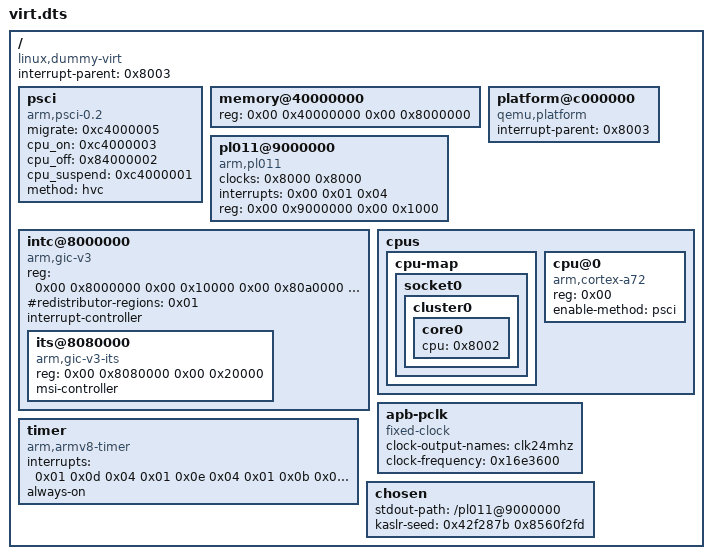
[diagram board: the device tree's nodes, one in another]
/dts-v1/;

/ {
	interrupt-parent = <0x8003>;
	#size-cells = <0x02>;
	#address-cells = <0x02>;
	compatible = "linux,dummy-virt";

	psci {
		migrate = <0xc4000005>;
		cpu_on = <0xc4000003>;
		cpu_off = <0x84000002>;
		cpu_suspend = <0xc4000001>;
		method = "hvc";
		compatible = "arm,psci-0.2\0arm,psci";
	};
	
	memory@40000000 {
		reg = <0x00 0x40000000 0x00 0x8000000>;
		device_type = "memory";
	};

	platform@c000000 {
		interrupt-parent = <0x8003>;
		ranges = <0x00 0x00 0xc000000 0x2000000>;
		#address-cells = <0x01>;
		#size-cells = <0x01>;
		compatible = "qemu,platform\0simple-bus";
	};

	pl011@9000000 {
		clock-names = "uartclk\0apb_pclk";
		clocks = <0x8000 0x8000>;
		interrupts = <0x00 0x01 0x04>;
		reg = <0x00 0x9000000 0x00 0x1000>;
		compatible = "arm,pl011\0arm,primecell";
	};

	intc@8000000 {
		phandle = <0x8003>;
		reg = <0x00 0x8000000 0x00 0x10000 0x00 0x80a0000 0x00 0xf60000>;
		#redistributor-regions = <0x01>;
		compatible = "arm,gic-v3";
		ranges;
		#size-cells = <0x02>;
		#address-cells = <0x02>;
		interrupt-controller;
		#interrupt-cells = <0x03>;

		its@8080000 {
			phandle = <0x8004>;
			reg = <0x00 0x8080000 0x00 0x20000>;
			msi-controller;
			compatible = "arm,gic-v3-its";
		};
	};

	cpus {
		#size-cells = <0x00>;
		#address-cells = <0x01>;

		cpu-map {

			socket0 {

				cluster0 {

					core0 {
						cpu = <0x8002>;
					};
					
				};
			};
		};

		cpu@0 {
			phandle = <0x8002>;
			reg = <0x00>;
			enable-method = "psci";
			compatible = "arm,cortex-a72";
			device_type = "cpu";
		};
	};

	timer {
		interrupts = <0x01 0x0d 0x04 0x01 0x0e 0x04 0x01 0x0b 0x04 0x01 0x0a 0x04>;
		always-on;
		compatible = "arm,armv8-timer\0arm,armv7-timer";
	};

	apb-pclk {
		phandle = <0x8000>;
		clock-output-names = "clk24mhz";
		clock-frequency = <0x16e3600>;
		#clock-cells = <0x00>;
		compatible = "fixed-clock";
	};

	chosen {
		stdout-path = "/pl011@9000000";
		kaslr-seed = <0x42f287b 0x8560f2fd>;
	};
};
